AUTOSAR XML (schema 4-2-2)
standard types defined: boolean, float32, float64, sint16, sint32, sint64, sint8, uint16, uint32, uint64, uint8, void
package /BSW/ImplementationDataTypes
  impl type ComM_InhibitionStatusType: compu {0x01=WakeupInhibitionActive, 0x02=LimitedToNoCom}, implementation-data-type=uint8
  impl type ComM_ModeType: compu {0=COMM_NO_COMMUNICATION, 1=COMM_SILENT_COMMUNICATION, 2=COMM_FULL_COMMUNICATION, 3=COMM_FULL_COMMUNICATION_WITH_WAKEUP_REQUEST}, implementation-data-type=uint8
  impl type ComM_UserHandleType: implementation-data-type=uint8
package /BSW/ModeDeclarationGroups
  mode declaration group ComMMode: category=ALPHABETIC_ORDER, initial-mode=COMM_NO_COMMUNICATION, on-transition-value=3
    mode COMM_FULL_COMMUNICATION: value=0
    mode COMM_NO_COMMUNICATION: value=1
    mode COMM_SILENT_COMMUNICATION: value=2
package /BSW/PortInterfaces
  client server interface ComM_UserRequest: service-kind=COM-MANAGER
    5 x operation:
      GetCurrentComMode: possible-error=[E_NOT_OK, E_OK]
        arg ComMode: type=ComM_ModeType, direction=OUT
      GetCurrentPNCComMode: possible-error=[E_MULTIPLE_PNC_ASSIGNED, E_NOT_OK, E_NO_PNC_ASSIGNED, E_OK]
        arg ComMode: type=ComM_ModeType, direction=OUT
      GetMaxComMode: possible-error=[E_NOT_OK, E_OK]
        arg ComMode: type=ComM_ModeType, direction=OUT
      GetRequestedComMode: possible-error=[E_NOT_OK, E_OK]
        arg ComMode: type=ComM_ModeType, direction=OUT
      RequestComMode: possible-error=[E_MODE_LIMITATION, E_NOT_OK, E_OK]
        arg ComMode: type=ComM_ModeType, direction=IN
    5 x error:
      E_MODE_LIMITATION: error-code=2
      E_MULTIPLE_PNC_ASSIGNED: error-code=3
      E_NOT_OK: error-code=1
      E_NO_PNC_ASSIGNED: error-code=4
      E_OK: error-code=0
  mode switch interface ComM_CurrentMode: service-kind=COM-MANAGER
    mode group ComMMode: type=ComMMode
package /BSW/SWCs
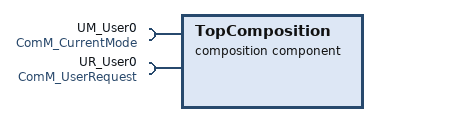
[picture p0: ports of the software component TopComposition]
  composition sw component type TopComposition
    require port UM_User0: required-interface=ComM_CurrentMode
    require port UR_User0: required-interface=ComM_UserRequest
